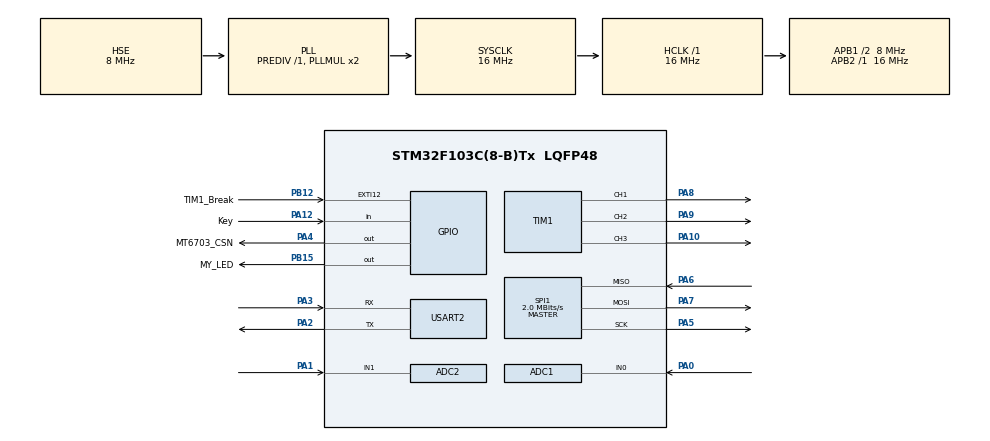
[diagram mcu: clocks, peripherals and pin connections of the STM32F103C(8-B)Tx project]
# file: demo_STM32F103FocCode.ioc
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ADC1.Channel-0\#ChannelRegularConversion=ADC_CHANNEL_0
ADC1.ContinuousConvMode=ENABLE
ADC1.NbrOfConversionFlag=1
ADC1.Rank-0\#ChannelRegularConversion=1
ADC1.SamplingTime-0\#ChannelRegularConversion=ADC_SAMPLETIME_1CYCLE_5
ADC1.master=1
ADC2.Channel-0\#ChannelRegularConversion=ADC_CHANNEL_1
ADC2.ContinuousConvMode=ENABLE
ADC2.NbrOfConversionFlag=1
ADC2.Rank-0\#ChannelRegularConversion=1
ADC2.SamplingTime-0\#ChannelRegularConversion=ADC_SAMPLETIME_1CYCLE_5
Dma.Request0=USART2_RX
Dma.Request1=USART2_TX
Dma.USART2_RX.0.Direction=DMA_PERIPH_TO_MEMORY
Dma.USART2_RX.0.Instance=DMA1_Channel6
Dma.USART2_RX.0.MemDataAlignment=DMA_MDATAALIGN_BYTE
Dma.USART2_RX.0.MemInc=DMA_MINC_ENABLE
Dma.USART2_RX.0.Mode=DMA_NORMAL
Dma.USART2_RX.0.PeriphDataAlignment=DMA_PDATAALIGN_BYTE
Dma.USART2_RX.0.PeriphInc=DMA_PINC_DISABLE
Dma.USART2_RX.0.Priority=DMA_PRIORITY_LOW
Dma.USART2_TX.1.Direction=DMA_MEMORY_TO_PERIPH
Dma.USART2_TX.1.Instance=DMA1_Channel7
Dma.USART2_TX.1.MemDataAlignment=DMA_MDATAALIGN_BYTE
Dma.USART2_TX.1.MemInc=DMA_MINC_ENABLE
Dma.USART2_TX.1.Mode=DMA_NORMAL
Dma.USART2_TX.1.PeriphDataAlignment=DMA_PDATAALIGN_BYTE
Dma.USART2_TX.1.PeriphInc=DMA_PINC_DISABLE
Dma.USART2_TX.1.Priority=DMA_PRIORITY_LOW
Mcu.Family=STM32F1
Mcu.Name=STM32F103C(8-B)Tx
Mcu.Package=LQFP48
NVIC.ADC1_2_IRQn=true\:0\:0\:false\:false\:true\:true\:true\:true
NVIC.DMA1_Channel6_IRQn=true\:0\:0\:false\:false\:true\:false\:true\:true
NVIC.DMA1_Channel7_IRQn=true\:0\:0\:false\:false\:true\:false\:true\:true
NVIC.PriorityGroup=NVIC_PRIORITYGROUP_4
NVIC.TIM2_IRQn=true\:0\:0\:false\:false\:true\:true\:true\:true
NVIC.TIM3_IRQn=true\:0\:0\:false\:false\:true\:true\:true\:true
NVIC.USART2_IRQn=true\:0\:0\:false\:false\:true\:true\:true\:true
PA0-WKUP.Signal=ADCx_IN0
PA1.Signal=ADCx_IN1
PA10.Signal=S_TIM1_CH3
PA12.GPIO_Label=Key
PA12.GPIO_PuPd=GPIO_PULLUP
PA12.Signal=GPIO_Input
PA13.Mode=Serial_Wire
PA13.Signal=SYS_JTMS-SWDIO
PA14.Mode=Serial_Wire
PA14.Signal=SYS_JTCK-SWCLK
PA2.Mode=Asynchronous
PA2.Signal=USART2_TX
PA3.Mode=Asynchronous
PA3.Signal=USART2_RX
PA4.GPIO_Label=MT6703_CSN
PA4.Signal=GPIO_Output
PA5.Mode=Full_Duplex_Master
PA5.Signal=SPI1_SCK
PA6.Mode=Full_Duplex_Master
PA6.Signal=SPI1_MISO
PA7.Mode=Full_Duplex_Master
PA7.Signal=SPI1_MOSI
PA8.Signal=S_TIM1_CH1
PA9.Signal=S_TIM1_CH2
PB12.GPIO_Label=TIM1_Break
PB12.Signal=GPXTI12
PB15.GPIO_Label=MY_LED
PB15.GPIO_PuPd=GPIO_PULLUP
PB15.PinState=GPIO_PIN_SET
PB15.Signal=GPIO_Output
PD0-OSC_IN.Mode=HSE-External-Oscillator
PD0-OSC_IN.Signal=RCC_OSC_IN
PD1-OSC_OUT.Mode=HSE-External-Oscillator
PD1-OSC_OUT.Signal=RCC_OSC_OUT
ProjectManager.HeapSize=0x200
ProjectManager.StackSize=0x400
ProjectManager.TargetToolchain=MDK-ARM V5.32
RCC.AHBFreq_Value=16000000
RCC.APB1CLKDivider=RCC_HCLK_DIV2
RCC.APB1Freq_Value=8000000
RCC.APB1TimFreq_Value=16000000
RCC.APB2Freq_Value=16000000
RCC.APB2TimFreq_Value=16000000
RCC.HCLKFreq_Value=16000000
RCC.PLLSourceVirtual=RCC_PLLSOURCE_HSE
RCC.SYSCLKFreq_VALUE=16000000
RCC.SYSCLKSource=RCC_SYSCLKSOURCE_PLLCLK
RCC.USBFreq_Value=16000000
SH.ADCx_IN0.0=ADC1_IN0,IN0
SH.ADCx_IN1.0=ADC2_IN1,IN1
SH.S_TIM1_CH1.0=TIM1_CH1,PWM Generation1 CH1
SH.S_TIM1_CH2.0=TIM1_CH2,PWM Generation2 CH2
SH.S_TIM1_CH3.0=TIM1_CH3,PWM Generation3 CH3
SPI1.BaudRatePrescaler=SPI_BAUDRATEPRESCALER_8
SPI1.CalculateBaudRate=2.0 MBits/s
SPI1.Direction=SPI_DIRECTION_2LINES
SPI1.Mode=SPI_MODE_MASTER
SPI1.VirtualType=VM_MASTER
TIM1.Channel-PWM\ Generation1\ CH1=TIM_CHANNEL_1
TIM1.Channel-PWM\ Generation2\ CH2=TIM_CHANNEL_2
TIM1.Channel-PWM\ Generation3\ CH3=TIM_CHANNEL_3
TIM2.AutoReloadPreload=TIM_AUTORELOAD_PRELOAD_ENABLE
TIM3.AutoReloadPreload=TIM_AUTORELOAD_PRELOAD_ENABLE
TIM3.Period=1000-1
TIM3.Prescaler=720-1
USART2.VirtualMode=VM_ASYNC
VP_TIM1_VS_ClockSourceINT.Mode=Internal
VP_TIM2_VS_ClockSourceINT.Mode=Internal
VP_TIM3_VS_ClockSourceINT.Mode=Internal
board=custom

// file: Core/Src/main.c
/* USER CODE BEGIN Header */
/**
  ******************************************************************************
  * @file           : main.c
  * @brief          : Main program body
  ******************************************************************************
  * @attention
  *
  * Copyright (c) 2025 STMicroelectronics.
  * All rights reserved.
  *
  * This software is licensed under terms that can be found in the LICENSE file
  * in the root directory of this software component.
  * If no LICENSE file comes with this software, it is provided AS-IS.
  *
  ******************************************************************************
  */
/* USER CODE END Header */
#include "main.h"
#include "adc.h"
#include "dma.h"
#include "spi.h"
#include "tim.h"
#include "usart.h"
#include "gpio.h"

/* USER CODE BEGIN Includes */
#include "printf.h"
#include "Foc.h"
#include "Motor_control.h"
/* USER CODE END Includes */

void SystemClock_Config(void);

int main(void)
{

  /* MCU Configuration--------------------------------------------------------*/

  /* Reset of all peripherals, Initializes the Flash interface and the Systick. */
  HAL_Init();

  /* Configure the system clock */
  SystemClock_Config();

  /* Initialize all configured peripherals */
  MX_GPIO_Init();
  MX_DMA_Init();
  MX_ADC1_Init();
  MX_ADC2_Init();
  MX_SPI1_Init();
  MX_TIM1_Init();
  MX_TIM2_Init();
  MX_USART2_UART_Init();
  MX_TIM3_Init();

  /* Infinite loop */
  while (1)
  {

  }
}

void SystemClock_Config(void)
{
  RCC_OscInitTypeDef RCC_OscInitStruct = {0};
  RCC_ClkInitTypeDef RCC_ClkInitStruct = {0};
  RCC_PeriphCLKInitTypeDef PeriphClkInit = {0};

  /** Initializes the RCC Oscillators according to the specified parameters
  * in the RCC_OscInitTypeDef structure.
  */
  RCC_OscInitStruct.OscillatorType = RCC_OSCILLATORTYPE_HSE;
  RCC_OscInitStruct.HSEState = RCC_HSE_ON;
  RCC_OscInitStruct.HSEPredivValue = RCC_HSE_PREDIV_DIV1;
  RCC_OscInitStruct.HSIState = RCC_HSI_ON;
  RCC_OscInitStruct.PLL.PLLState = RCC_PLL_ON;
  RCC_OscInitStruct.PLL.PLLSource = RCC_PLLSOURCE_HSE;
  RCC_OscInitStruct.PLL.PLLMUL = RCC_PLL_MUL2;
  if (HAL_RCC_OscConfig(&RCC_OscInitStruct) != HAL_OK)
  {
    Error_Handler();
  }

  /** Initializes the CPU, AHB and APB buses clocks
  */
  RCC_ClkInitStruct.ClockType = RCC_CLOCKTYPE_HCLK|RCC_CLOCKTYPE_SYSCLK
                              |RCC_CLOCKTYPE_PCLK1|RCC_CLOCKTYPE_PCLK2;
  RCC_ClkInitStruct.SYSCLKSource = RCC_SYSCLKSOURCE_PLLCLK;
  RCC_ClkInitStruct.AHBCLKDivider = RCC_SYSCLK_DIV1;
  RCC_ClkInitStruct.APB1CLKDivider = RCC_HCLK_DIV2;
  RCC_ClkInitStruct.APB2CLKDivider = RCC_HCLK_DIV1;

  if (HAL_RCC_ClockConfig(&RCC_ClkInitStruct, FLASH_LATENCY_0) != HAL_OK)
  {
    Error_Handler();
  }
  PeriphClkInit.PeriphClockSelection = RCC_PERIPHCLK_ADC;
  PeriphClkInit.AdcClockSelection = RCC_ADCPCLK2_DIV2;
  if (HAL_RCCEx_PeriphCLKConfig(&PeriphClkInit) != HAL_OK)
  {
    Error_Handler();
  }
}

void Error_Handler(void)
{
  __disable_irq();
  while (1)
  {
  }
}
